# tviic2d6mddr register map
Vendor: Cypress Semiconductor; Series: tviic2d6mddr; File version: 1.0
CPU: CM7 r0p1, little endian, MPU, FPU, VTOR, 3 interrupt priority bits
Registers are 32-bit, read-write, reset 0x0 unless marked. A register's access mark holds for its fields unless they carry their own. Offsets are from the block's base; [hi:lo] are bit positions; lines under a group give offsets from that group; {n}, {i} and the like mark numbered series; 'fields as' and 'values as' point back to an identical list.

## VIDEOSS0 (part 5 of 18) — Video and Graphics Subsystem IP
Base 0x40A00000
0x80000 VIDEOIO group — Video I/O Core
  0x00 SUBIO group — Sub Interface
    0x10000 COMPENG group — Composition Engine
      0x00 COMPENGCFG group — Top-Level
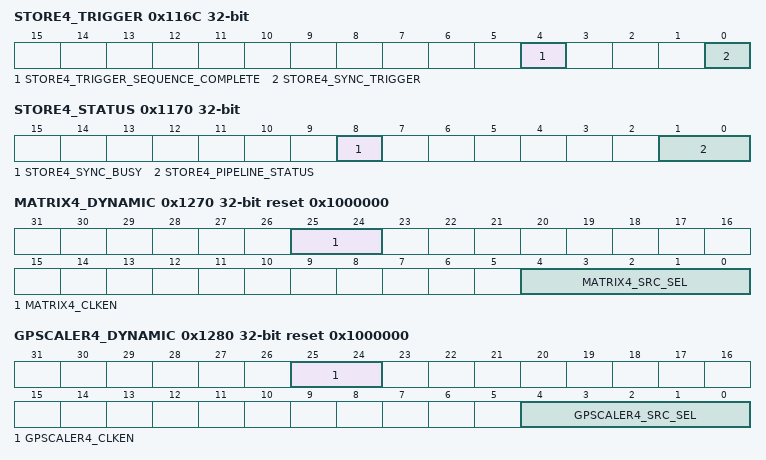
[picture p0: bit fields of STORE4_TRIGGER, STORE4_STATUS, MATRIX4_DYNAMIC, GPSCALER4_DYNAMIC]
        0x116C STORE4_TRIGGER wo reset not defined — Trigger bits for pixel engine configuration of store4
          [4] STORE4_TRIGGER_SEQUENCE_COMPLETE — By writing a '1' to this register field, you can trigger the store4 sequence complete interrupt that will occur as soon as the pipeline with the endpoint store4 is empty. This interrupt will also occur if the pipeline is already empty when this field is written. The interrupt will not occur if this field is not written. The interrupt will occur exactly as often as this field is written, assuming that this field is not written again until the interrupt has occured after a previous trigger.
          [0] STORE4_SYNC_TRIGGER — Writing a '1' to this field triggers reconfiguration of the pipeline with endpoint store4
        0x1170 STORE4_STATUS ro — Status information for pixel engine configuration of store4
          [8] STORE4_SYNC_BUSY — Synchronization busy status of store4 endpoint
            0=IDLE (store4 synchronizer is idle); 1=BUSY (store4 synchronizer is busy)
          [1:0] STORE4_PIPELINE_STATUS — Status of pipeline with endpoint store4
            0=EMPTY (Pipeline with endpoint store4 is empty); 1=RUNNING (Pipeline with endpoint store4 is currently processing one operation); 2=RUNNING_RETRIGGERED (Pipeline with endpoint store4 is currently processing one operation with a second one already kicked to be processed afterwards); 3=RSVD (N/A)
        0x1180 FETCHLAYER0_STATUS ro reset not defined — Status information for pixel engine configuration of fetchlayer0
          [18:16] FETCHLAYER0_SEL — Status of the connection of the fetchlayer0 module
            1=EXTDST0 (fetchlayer0 module is used from extdst0 processing path); 2=EXTDST4 (fetchlayer0 module is used from extdst4 processing path); 3=EXTDST1 (fetchlayer0 module is used from extdst1 processing path); 4=EXTDST5 (fetchlayer0 module is used from extdst5 processing path); 5=STORE4 (fetchlayer0 module is used from store4 processing path); 0=DISABLE (fetchlayer0 module is not used)
        0x11A0 FETCHDECODE4_DYNAMIC — Dynamic pixel engine configuration for fetchdecode4
          [4:0] FETCHDECODE4_SRC_SEL — Selection of the source for the src input of the fetchdecode4 module
            0=DISABLE (Unit fetchdecode4 input port src is disabled); 13=FETCHECO4 (Unit fetchdecode4 input port src is connected to output of unit fetcheco4); 20=GPSCALER4 (Unit fetchdecode4 input port src is connected to output of unit gpscaler4)
        0x11A4 FETCHDECODE4_STATUS ro reset not defined — Status information for pixel engine configuration of fetchdecode4
          [18:16] FETCHDECODE4_SEL — Status of the connection of the fetchdecode4 module
            1=EXTDST0 (fetchdecode4 module is used from extdst0 processing path); 2=EXTDST4 (fetchdecode4 module is used from extdst4 processing path); 3=EXTDST1 (fetchdecode4 module is used from extdst1 processing path); 4=EXTDST5 (fetchdecode4 module is used from extdst5 processing path); 5=STORE4 (fetchdecode4 module is used from store4 processing path); 0=DISABLE (fetchdecode4 module is not used)
        0x11C0 FETCHECO4_STATUS ro reset not defined — Status information for pixel engine configuration of fetcheco4
          [18:16] FETCHECO4_SEL — Status of the connection of the fetcheco4 module
            1=EXTDST0 (fetcheco4 module is used from extdst0 processing path); 2=EXTDST4 (fetcheco4 module is used from extdst4 processing path); 3=EXTDST1 (fetcheco4 module is used from extdst1 processing path); 4=EXTDST5 (fetcheco4 module is used from extdst5 processing path); 5=STORE4 (fetcheco4 module is used from store4 processing path); 0=DISABLE (fetcheco4 module is not used)
        0x1200 FETCHWARP1_DYNAMIC — Dynamic pixel engine configuration for fetchwarp1
          [4:0] FETCHWARP1_SRC_SEL — Selection of the source for the src input of the fetchwarp1 module
            0=DISABLE (Unit fetchwarp1 input port src is disabled); 15=FETCHECO1 (Unit fetchwarp1 input port src is connected to output of unit fetcheco1)
        0x1204 FETCHWARP1_STATUS ro reset not defined — Status information for pixel engine configuration of fetchwarp1
          [18:16] FETCHWARP1_SEL — Status of the connection of the fetchwarp1 module
            1=EXTDST0 (fetchwarp1 module is used from extdst0 processing path); 2=EXTDST4 (fetchwarp1 module is used from extdst4 processing path); 3=EXTDST1 (fetchwarp1 module is used from extdst1 processing path); 4=EXTDST5 (fetchwarp1 module is used from extdst5 processing path); 5=STORE4 (fetchwarp1 module is used from store4 processing path); 0=DISABLE (fetchwarp1 module is not used)
        0x1208 FETCHECO1_STATUS ro reset not defined — Status information for pixel engine configuration of fetcheco1
          [18:16] FETCHECO1_SEL — Status of the connection of the fetcheco1 module
            1=EXTDST0 (fetcheco1 module is used from extdst0 processing path); 2=EXTDST4 (fetcheco1 module is used from extdst4 processing path); 3=EXTDST1 (fetcheco1 module is used from extdst1 processing path); 4=EXTDST5 (fetcheco1 module is used from extdst5 processing path); 5=STORE4 (fetcheco1 module is used from store4 processing path); 0=DISABLE (fetcheco1 module is not used)
        0x1220 FETCHLAYER1_STATUS ro reset not defined — Status information for pixel engine configuration of fetchlayer1
          [18:16] FETCHLAYER1_SEL — Status of the connection of the fetchlayer1 module
            1=EXTDST0 (fetchlayer1 module is used from extdst0 processing path); 2=EXTDST4 (fetchlayer1 module is used from extdst4 processing path); 3=EXTDST1 (fetchlayer1 module is used from extdst1 processing path); 4=EXTDST5 (fetchlayer1 module is used from extdst5 processing path); 5=STORE4 (fetchlayer1 module is used from store4 processing path); 0=DISABLE (fetchlayer1 module is not used)
        0x1240 FETCHDECODE0_DYNAMIC — Dynamic pixel engine configuration for fetchdecode0
          [4:0] FETCHDECODE0_SRC_SEL — Selection of the source for the src input of the fetchdecode0 module
            0=DISABLE (Unit fetchdecode0 input port src is disabled); 15=FETCHECO1 (Unit fetchdecode0 input port src is connected to output of unit fetcheco1); 13=FETCHECO4 (Unit fetchdecode0 input port src is connected to output of unit fetcheco4)
        0x1244 FETCHDECODE0_STATUS ro reset not defined — Status information for pixel engine configuration of fetchdecode0
          [18:16] FETCHDECODE0_SEL — Status of the connection of the fetchdecode0 module
            1=EXTDST0 (fetchdecode0 module is used from extdst0 processing path); 2=EXTDST4 (fetchdecode0 module is used from extdst4 processing path); 3=EXTDST1 (fetchdecode0 module is used from extdst1 processing path); 4=EXTDST5 (fetchdecode0 module is used from extdst5 processing path); 5=STORE4 (fetchdecode0 module is used from store4 processing path); 0=DISABLE (fetchdecode0 module is not used)
        0x1260 GAMMACOR4_DYNAMIC — Dynamic pixel engine configuration for gammacor4
          [4:0] GAMMACOR4_SRC_SEL — Selection of the source for the src input of the gammacor4 module
            0=DISABLE (Unit gammacor4 input port src is disabled); 9=EXTSRC4 (Unit gammacor4 input port src is connected to output of unit extsrc4); 12=FETCHDECODE4 (Unit gammacor4 input port src is connected to output of unit fetchdecode4)
        0x1264 GAMMACOR4_STATUS ro reset not defined — Status information for pixel engine configuration of gammacor4
          [18:16] GAMMACOR4_SEL — Status of the connection of the gammacor4 module
            1=EXTDST0 (gammacor4 module is used from extdst0 processing path); 2=EXTDST4 (gammacor4 module is used from extdst4 processing path); 3=EXTDST1 (gammacor4 module is used from extdst1 processing path); 4=EXTDST5 (gammacor4 module is used from extdst5 processing path); 5=STORE4 (gammacor4 module is used from store4 processing path); 0=DISABLE (gammacor4 module is not used)
        0x1270 MATRIX4_DYNAMIC reset 0x1000000 — Dynamic pixel engine configuration for matrix4
          [25:24] MATRIX4_CLKEN — Enable of matrix4 clock (this setting has to be the same for all modules of one processing pipeline). If a submodule is enabled and FULL is used, then the register [endpoint_name]_clk must be set to 0x80.
            0=DISABLE (Clock for matrix4 is disabled); 1=AUTOMATIC (Clock is enabled if unit is used, frequency is defined by the register setting for this pipeline (see [endpoint_name]_Static register)); 3=FULL (Clock for matrix4 is without gating)
          [4:0] MATRIX4_SRC_SEL — Selection of the source for the src input of the matrix4 module
            0=DISABLE (Unit matrix4 input port src is disabled); 18=GAMMACOR4 (Unit matrix4 input port src is connected to output of unit gammacor4)
        0x1274 MATRIX4_STATUS ro reset not defined — Status information for pixel engine configuration of matrix4
          [18:16] MATRIX4_SEL — Status of the connection of the matrix4 module
            1=EXTDST0 (matrix4 module is used from extdst0 processing path); 2=EXTDST4 (matrix4 module is used from extdst4 processing path); 3=EXTDST1 (matrix4 module is used from extdst1 processing path); 4=EXTDST5 (matrix4 module is used from extdst5 processing path); 5=STORE4 (matrix4 module is used from store4 processing path); 0=DISABLE (matrix4 module is not used)
        0x1280 GPSCALER4_DYNAMIC reset 0x1000000 — Dynamic pixel engine configuration for gpscaler4
          [25:24] GPSCALER4_CLKEN — Enable of gpscaler4 clock (this setting has to be the same for all modules of one processing pipeline). If a submodule is enabled and FULL is used, then the register [endpoint_name]_clk must be set to 0x80.
            0=DISABLE (Clock for gpscaler4 is disabled); 1=AUTOMATIC (Clock is enabled if unit is used, frequency is defined by the register setting for this pipeline (see [endpoint_name]_Static register)); 3=FULL (Clock for gpscaler4 is without gating)
          [4:0] GPSCALER4_SRC_SEL — Selection of the source for the src input of the gpscaler4 module
            0=DISABLE (Unit gpscaler4 input port src is disabled); 19=MATRIX4 (Unit gpscaler4 input port src is connected to output of unit matrix4); 13=FETCHECO4 (Unit gpscaler4 input port src is connected to output of unit fetcheco4)
        0x1284 GPSCALER4_STATUS ro reset not defined — Status information for pixel engine configuration of gpscaler4
          [18:16] GPSCALER4_SEL — Status of the connection of the gpscaler4 module
            1=EXTDST0 (gpscaler4 module is used from extdst0 processing path); 2=EXTDST4 (gpscaler4 module is used from extdst4 processing path); 3=EXTDST1 (gpscaler4 module is used from extdst1 processing path); 4=EXTDST5 (gpscaler4 module is used from extdst5 processing path); 5=STORE4 (gpscaler4 module is used from store4 processing path); 0=DISABLE (gpscaler4 module is not used)
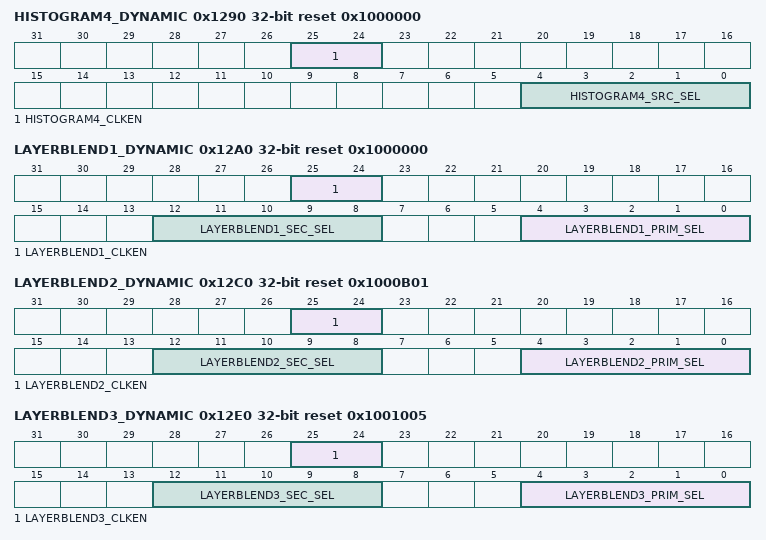
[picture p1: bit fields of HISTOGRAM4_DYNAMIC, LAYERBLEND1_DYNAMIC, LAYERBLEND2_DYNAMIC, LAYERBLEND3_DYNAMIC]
        0x1290 HISTOGRAM4_DYNAMIC reset 0x1000000 — Dynamic pixel engine configuration for histogram4
          [25:24] HISTOGRAM4_CLKEN — Enable of histogram4 clock (this setting has to be the same for all modules of one processing pipeline). If a submodule is enabled and FULL is used, then the register [endpoint_name]_clk must be set to 0x80.
            0=DISABLE (Clock for histogram4 is disabled); 1=AUTOMATIC (Clock is enabled if unit is used, frequency is defined by the register setting for this pipeline (see [endpoint_name]_Static register)); 3=FULL (Clock for histogram4 is without gating)
          [4:0] HISTOGRAM4_SRC_SEL — Selection of the source for the src input of the histogram4 module
            0=DISABLE (Unit histogram4 input port src is disabled); 9=EXTSRC4 (Unit histogram4 input port src is connected to output of unit extsrc4); 12=FETCHDECODE4 (Unit histogram4 input port src is connected to output of unit fetchdecode4); 18=GAMMACOR4 (Unit histogram4 input port src is connected to output of unit gammacor4); 19=MATRIX4 (Unit histogram4 input port src is connected to output of unit matrix4)
        0x1294 HISTOGRAM4_STATUS ro reset not defined — Status information for pixel engine configuration of histogram4
          [18:16] HISTOGRAM4_SEL — Status of the connection of the histogram4 module
            1=EXTDST0 (histogram4 module is used from extdst0 processing path); 2=EXTDST4 (histogram4 module is used from extdst4 processing path); 3=EXTDST1 (histogram4 module is used from extdst1 processing path); 4=EXTDST5 (histogram4 module is used from extdst5 processing path); 5=STORE4 (histogram4 module is used from store4 processing path); 0=DISABLE (histogram4 module is not used)
        0x12A0 LAYERBLEND1_DYNAMIC reset 0x1000000 — Dynamic pixel engine configuration for layerblend1
          [25:24] LAYERBLEND1_CLKEN — Enable of layerblend1 clock (this setting has to be the same for all modules of one processing pipeline). If a submodule is enabled and FULL is used, then the register [endpoint_name]_clk must be set to 0x80.
            0=DISABLE (Clock for layerblend1 is disabled); 1=AUTOMATIC (Clock is enabled if unit is used, frequency is defined by the register setting for this pipeline (see [endpoint_name]_Static register)); 3=FULL (Clock for layerblend1 is without gating)
          [12:8] LAYERBLEND1_SEC_SEL — Selection of the source for the sec input of the layerblend1 module
            0=DISABLE (Unit layerblend1 input port sec is disabled); 12=FETCHDECODE4 (Unit layerblend1 input port sec is connected to output of unit fetchdecode4); 14=FETCHWARP1 (Unit layerblend1 input port sec is connected to output of unit fetchwarp1); 17=FETCHDECODE0 (Unit layerblend1 input port sec is connected to output of unit fetchdecode0); 19=MATRIX4 (Unit layerblend1 input port sec is connected to output of unit matrix4); 20=GPSCALER4 (Unit layerblend1 input port sec is connected to output of unit gpscaler4); 11=FETCHLAYER0 (Unit layerblend1 input port sec is connected to output of unit fetchlayer0); 16=FETCHLAYER1 (Unit layerblend1 input port sec is connected to output of unit fetchlayer1)
          [4:0] LAYERBLEND1_PRIM_SEL — Selection of the source for the prim input of the layerblend1 module
            0=DISABLE (Unit layerblend1 input port prim is disabled); 1=CONSTFRAME0 (Unit layerblend1 input port prim is connected to output of unit constframe0); 5=CONSTFRAME1 (Unit layerblend1 input port prim is connected to output of unit constframe1); 3=CONSTFRAME4 (Unit layerblend1 input port prim is connected to output of unit constframe4); 7=CONSTFRAME5 (Unit layerblend1 input port prim is connected to output of unit constframe5); 19=MATRIX4 (Unit layerblend1 input port prim is connected to output of unit matrix4); 20=GPSCALER4 (Unit layerblend1 input port prim is connected to output of unit gpscaler4); 9=EXTSRC4 (Unit layerblend1 input port prim is connected to output of unit extsrc4)
        {0x1284+0x20*m} LAYERBLEND{m}_STATUS ro reset not defined (m=1..5) — Status information for pixel engine configuration of layerblend{m}
          [18:16] LAYERBLEND{m}_SEL — Status of the connection of the layerblend{m} module
            1=EXTDST0 (layerblend{m} module is used from extdst0 processing path); 2=EXTDST4 (layerblend{m} module is used from extdst4 processing path); 3=EXTDST1 (layerblend{m} module is used from extdst1 processing path); 4=EXTDST5 (layerblend{m} module is used from extdst5 processing path); 5=STORE4 (layerblend{m} module is used from store4 processing path); 0=DISABLE (layerblend{m} module is not used)
        0x12C0 LAYERBLEND2_DYNAMIC reset 0x1000B01 — Dynamic pixel engine configuration for layerblend2
          [25:24] LAYERBLEND2_CLKEN — Enable of layerblend2 clock (this setting has to be the same for all modules of one processing pipeline). If a submodule is enabled and FULL is used, then the register [endpoint_name]_clk must be set to 0x80.
            0=DISABLE (Clock for layerblend2 is disabled); 1=AUTOMATIC (Clock is enabled if unit is used, frequency is defined by the register setting for this pipeline (see [endpoint_name]_Static register)); 3=FULL (Clock for layerblend2 is without gating)
          [12:8] LAYERBLEND2_SEC_SEL — Selection of the source for the sec input of the layerblend2 module
            0=DISABLE (Unit layerblend2 input port sec is disabled); 12=FETCHDECODE4 (Unit layerblend2 input port sec is connected to output of unit fetchdecode4); 14=FETCHWARP1 (Unit layerblend2 input port sec is connected to output of unit fetchwarp1); 17=FETCHDECODE0 (Unit layerblend2 input port sec is connected to output of unit fetchdecode0); 19=MATRIX4 (Unit layerblend2 input port sec is connected to output of unit matrix4); 20=GPSCALER4 (Unit layerblend2 input port sec is connected to output of unit gpscaler4); 11=FETCHLAYER0 (Unit layerblend2 input port sec is connected to output of unit fetchlayer0); 16=FETCHLAYER1 (Unit layerblend2 input port sec is connected to output of unit fetchlayer1)
          [4:0] LAYERBLEND2_PRIM_SEL — Selection of the source for the prim input of the layerblend2 module
            0=DISABLE (Unit layerblend2 input port prim is disabled); 1=CONSTFRAME0 (Unit layerblend2 input port prim is connected to output of unit constframe0); 5=CONSTFRAME1 (Unit layerblend2 input port prim is connected to output of unit constframe1); 3=CONSTFRAME4 (Unit layerblend2 input port prim is connected to output of unit constframe4); 7=CONSTFRAME5 (Unit layerblend2 input port prim is connected to output of unit constframe5); 19=MATRIX4 (Unit layerblend2 input port prim is connected to output of unit matrix4); 20=GPSCALER4 (Unit layerblend2 input port prim is connected to output of unit gpscaler4); 9=EXTSRC4 (Unit layerblend2 input port prim is connected to output of unit extsrc4); 22=LAYERBLEND1 (Unit layerblend2 input port prim is connected to output of unit layerblend1)
        0x12E0 LAYERBLEND3_DYNAMIC reset 0x1001005 — Dynamic pixel engine configuration for layerblend3
          [25:24] LAYERBLEND3_CLKEN — Enable of layerblend3 clock (this setting has to be the same for all modules of one processing pipeline). If a submodule is enabled and FULL is used, then the register [endpoint_name]_clk must be set to 0x80.
            0=DISABLE (Clock for layerblend3 is disabled); 1=AUTOMATIC (Clock is enabled if unit is used, frequency is defined by the register setting for this pipeline (see [endpoint_name]_Static register)); 3=FULL (Clock for layerblend3 is without gating)
          [12:8] LAYERBLEND3_SEC_SEL — Selection of the source for the sec input of the layerblend3 module
            0=DISABLE (Unit layerblend3 input port sec is disabled); 12=FETCHDECODE4 (Unit layerblend3 input port sec is connected to output of unit fetchdecode4); 14=FETCHWARP1 (Unit layerblend3 input port sec is connected to output of unit fetchwarp1); 17=FETCHDECODE0 (Unit layerblend3 input port sec is connected to output of unit fetchdecode0); 19=MATRIX4 (Unit layerblend3 input port sec is connected to output of unit matrix4); 20=GPSCALER4 (Unit layerblend3 input port sec is connected to output of unit gpscaler4); 11=FETCHLAYER0 (Unit layerblend3 input port sec is connected to output of unit fetchlayer0); 16=FETCHLAYER1 (Unit layerblend3 input port sec is connected to output of unit fetchlayer1)
          [4:0] LAYERBLEND3_PRIM_SEL — Selection of the source for the prim input of the layerblend3 module
            0=DISABLE (Unit layerblend3 input port prim is disabled); 1=CONSTFRAME0 (Unit layerblend3 input port prim is connected to output of unit constframe0); 5=CONSTFRAME1 (Unit layerblend3 input port prim is connected to output of unit constframe1); 3=CONSTFRAME4 (Unit layerblend3 input port prim is connected to output of unit constframe4); 7=CONSTFRAME5 (Unit layerblend3 input port prim is connected to output of unit constframe5); 19=MATRIX4 (Unit layerblend3 input port prim is connected to output of unit matrix4); 20=GPSCALER4 (Unit layerblend3 input port prim is connected to output of unit gpscaler4); 9=EXTSRC4 (Unit layerblend3 input port prim is connected to output of unit extsrc4); 23=LAYERBLEND2 (Unit layerblend3 input port prim is connected to output of unit layerblend2); 22=LAYERBLEND1 (Unit layerblend3 input port prim is connected to output of unit layerblend1)
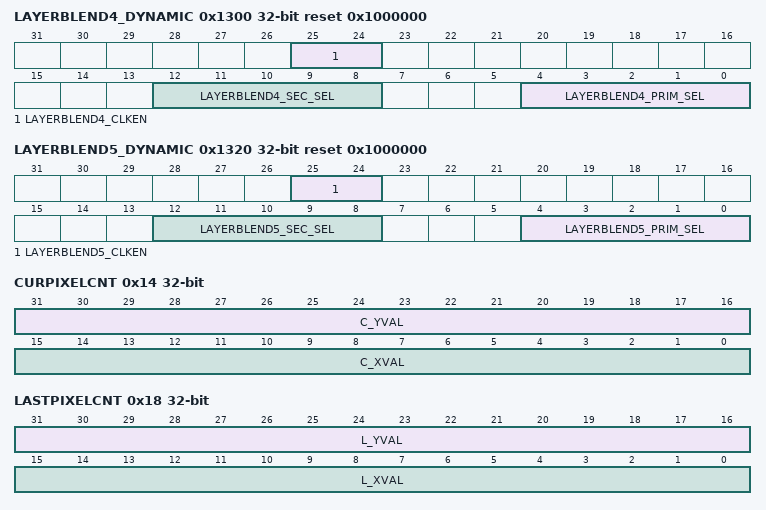
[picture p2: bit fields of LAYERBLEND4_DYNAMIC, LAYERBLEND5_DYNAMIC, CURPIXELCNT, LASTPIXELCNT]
        0x1300 LAYERBLEND4_DYNAMIC reset 0x1000000 — Dynamic pixel engine configuration for layerblend4
          [25:24] LAYERBLEND4_CLKEN — Enable of layerblend4 clock (this setting has to be the same for all modules of one processing pipeline). If a submodule is enabled and FULL is used, then the register [endpoint_name]_clk must be set to 0x80.
            0=DISABLE (Clock for layerblend4 is disabled); 1=AUTOMATIC (Clock is enabled if unit is used, frequency is defined by the register setting for this pipeline (see [endpoint_name]_Static register)); 3=FULL (Clock for layerblend4 is without gating)
          [12:8] LAYERBLEND4_SEC_SEL — Selection of the source for the sec input of the layerblend4 module
            0=DISABLE (Unit layerblend4 input port sec is disabled); 12=FETCHDECODE4 (Unit layerblend4 input port sec is connected to output of unit fetchdecode4); 14=FETCHWARP1 (Unit layerblend4 input port sec is connected to output of unit fetchwarp1); 17=FETCHDECODE0 (Unit layerblend4 input port sec is connected to output of unit fetchdecode0); 19=MATRIX4 (Unit layerblend4 input port sec is connected to output of unit matrix4); 20=GPSCALER4 (Unit layerblend4 input port sec is connected to output of unit gpscaler4); 11=FETCHLAYER0 (Unit layerblend4 input port sec is connected to output of unit fetchlayer0); 16=FETCHLAYER1 (Unit layerblend4 input port sec is connected to output of unit fetchlayer1)
          [4:0] LAYERBLEND4_PRIM_SEL — Selection of the source for the prim input of the layerblend4 module
            0=DISABLE (Unit layerblend4 input port prim is disabled); 1=CONSTFRAME0 (Unit layerblend4 input port prim is connected to output of unit constframe0); 5=CONSTFRAME1 (Unit layerblend4 input port prim is connected to output of unit constframe1); 3=CONSTFRAME4 (Unit layerblend4 input port prim is connected to output of unit constframe4); 7=CONSTFRAME5 (Unit layerblend4 input port prim is connected to output of unit constframe5); 19=MATRIX4 (Unit layerblend4 input port prim is connected to output of unit matrix4); 20=GPSCALER4 (Unit layerblend4 input port prim is connected to output of unit gpscaler4); 9=EXTSRC4 (Unit layerblend4 input port prim is connected to output of unit extsrc4); 24=LAYERBLEND3 (Unit layerblend4 input port prim is connected to output of unit layerblend3); 23=LAYERBLEND2 (Unit layerblend4 input port prim is connected to output of unit layerblend2); 22=LAYERBLEND1 (Unit layerblend4 input port prim is connected to output of unit layerblend1)
        0x1320 LAYERBLEND5_DYNAMIC reset 0x1000000 — Dynamic pixel engine configuration for layerblend5
          [25:24] LAYERBLEND5_CLKEN — Enable of layerblend5 clock (this setting has to be the same for all modules of one processing pipeline). If a submodule is enabled and FULL is used, then the register [endpoint_name]_clk must be set to 0x80.
            0=DISABLE (Clock for layerblend5 is disabled); 1=AUTOMATIC (Clock is enabled if unit is used, frequency is defined by the register setting for this pipeline (see [endpoint_name]_Static register)); 3=FULL (Clock for layerblend5 is without gating)
          [12:8] LAYERBLEND5_SEC_SEL — Selection of the source for the sec input of the layerblend5 module
            0=DISABLE (Unit layerblend5 input port sec is disabled); 12=FETCHDECODE4 (Unit layerblend5 input port sec is connected to output of unit fetchdecode4); 14=FETCHWARP1 (Unit layerblend5 input port sec is connected to output of unit fetchwarp1); 17=FETCHDECODE0 (Unit layerblend5 input port sec is connected to output of unit fetchdecode0); 19=MATRIX4 (Unit layerblend5 input port sec is connected to output of unit matrix4); 20=GPSCALER4 (Unit layerblend5 input port sec is connected to output of unit gpscaler4); 11=FETCHLAYER0 (Unit layerblend5 input port sec is connected to output of unit fetchlayer0); 16=FETCHLAYER1 (Unit layerblend5 input port sec is connected to output of unit fetchlayer1)
          [4:0] LAYERBLEND5_PRIM_SEL — Selection of the source for the prim input of the layerblend5 module
            0=DISABLE (Unit layerblend5 input port prim is disabled); 1=CONSTFRAME0 (Unit layerblend5 input port prim is connected to output of unit constframe0); 5=CONSTFRAME1 (Unit layerblend5 input port prim is connected to output of unit constframe1); 3=CONSTFRAME4 (Unit layerblend5 input port prim is connected to output of unit constframe4); 7=CONSTFRAME5 (Unit layerblend5 input port prim is connected to output of unit constframe5); 19=MATRIX4 (Unit layerblend5 input port prim is connected to output of unit matrix4); 20=GPSCALER4 (Unit layerblend5 input port prim is connected to output of unit gpscaler4); 9=EXTSRC4 (Unit layerblend5 input port prim is connected to output of unit extsrc4); {v}=LAYERBLEND{v-21} (Unit layerblend5 input port prim is connected to output of unit layerblend{v-21}) (v=22..25)
        0x1340 EXTSRC8_STATUS ro reset not defined — Status information for pixel engine configuration of extsrc8
          [18:16] EXTSRC8_SEL — Status of the connection of the extsrc8 module
            1=EXTDST0 (extsrc8 module is used from extdst0 processing path); 2=EXTDST4 (extsrc8 module is used from extdst4 processing path); 3=EXTDST1 (extsrc8 module is used from extdst1 processing path); 4=EXTDST5 (extsrc8 module is used from extdst5 processing path); 5=STORE4 (extsrc8 module is used from store4 processing path); 0=DISABLE (extsrc8 module is not used)
      0x2000 CONSTFRAME0 group — ConstFrame #0 (Content)
        0x00 STATICCONTROL — ConstFrame unit static control register
          [0] SHDEN — Enables shadowing of all RWS type registers (0=write_through, 1=shadowed).
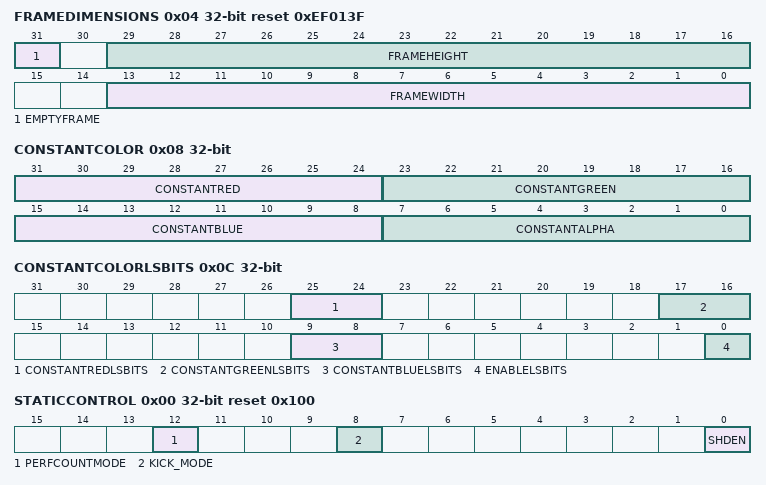
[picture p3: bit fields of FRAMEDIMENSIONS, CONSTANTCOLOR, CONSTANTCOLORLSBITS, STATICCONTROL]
        0x04 FRAMEDIMENSIONS reset 0xEF013F — Output frame dimensions.
          [31] EMPTYFRAME — When enabled output frame is empty. FrameWidth/Height settings have no effect then. Can be used to load shadows or to generate synchronization signals only (frame/sequence complete).
          [29:16] FRAMEHEIGHT — Frame height in pixels minus one.
          [13:0] FRAMEWIDTH — Frame width in pixels minus one.
        0x08 CONSTANTCOLOR — 8-bit constant frame color components.
          [31:24] CONSTANTRED — Red component.
          [23:16] CONSTANTGREEN — Green component.
          [15:8] CONSTANTBLUE — Blue component.
          [7:0] CONSTANTALPHA — Alpha component.
        0x0C CONSTANTCOLORLSBITS — LSBits for 10-bit constant frame color components (optional).
          [25:24] CONSTANTREDLSBITS — LSBits of 10-bit red component.
          [17:16] CONSTANTGREENLSBITS — LSBits of 10-bit green component.
          [9:8] CONSTANTBLUELSBITS — LSBits of 10-bit blue component.
          [0] ENABLELSBITS — If enabled, the two least significant bits of 10-bit color components are taken from this register. Otherwise the two most significant bits from 8-bit values in ConstantColor register are taken.
        0x10 CONTROLTRIGGER wo reset not defined — ConstFrame unit trigger register
          [0] SHDTOKGEN — Writing a 1 to this will load shadow registers into the active configuration with the next start of frame and send a shadow load token to subsequent units.
        0x14 START wo reset not defined — ConstFrame unit start register
          [0] START — Writing a one starts processing, it is recommended to use this for debug purposes only.
      0x2400 EXTDST0 group — ExtDst #0 (Content)
        0x00 STATICCONTROL reset 0x100 — External Destination static control register
          [12] PERFCOUNTMODE — Value 1 enables performance counter mode, which does not generate an output frame but processes input data as fast as possible instead. Can be used to determine the maximum possible read-out performance of display buffers.
          [8] KICK_MODE — Operation mode of generated kick signal
            0=SOFTWARE (kick generation by KICK field only); 1=EXTERNAL (kick signal from external allowed)
          [0] SHDEN — Enables shadowing of all RWS type registers (0=write_through, 1=shadowed).
        0x04 CONTROL — External Destination shadowed control register
          [0] GAMMAAPPLYENABLE — Enable gamma conversion stage to apply gamma function. This gamma function converts the pixel data from linear color space to non-linear color space before they are output.
        0x08 SOFTWAREKICK wo reset not defined — External Destination software kick
          [0] KICK — Software kick, forces a kick signal independent of KICK_MODE. Write 1 to send kick.
        0x0C STATUS — External Destination Unit current status
          [0] CNT_ERR_STS — Pixel count error
        0x10 CONTROLWORD ro reset not defined — Value of last received control word
          [31:0] CW_VAL
        0x14 CURPIXELCNT ro reset not defined — pixel count of currently running frame
          [31:16] C_YVAL — value of vertical line counter, internal counter counting from max-1 to 0
          [15:0] C_XVAL — value of horizontal pixel counter, internal counter counting from max-1 to 0
        0x18 LASTPIXELCNT ro reset not defined — pixel count between last two control words
          [31:16] L_YVAL — value of vertical line counter
          [15:0] L_XVAL — value of horizontal pixel counter
        0x1C PERFCOUNTER ro — Performance counter result
          [31:0] PERFRESULT — Returns the performance counter value. Returns number of cycles of the last frame on the input. To calculate the performance divide the known number of pixels of the frame by this number. For debug purposes only, read when stable only, otherwise read data might be corrupted.
      0x2800 CONSTFRAME4 group — ConstFrame #4 (Safety)
        0x00 STATICCONTROL — ConstFrame unit static control register
          fields as VIDEOIO.SUBIO.COMPENG.CONSTFRAME0.STATICCONTROL
        0x04 FRAMEDIMENSIONS reset 0xEF013F — Output frame dimensions.
          fields as VIDEOIO.SUBIO.COMPENG.CONSTFRAME0.FRAMEDIMENSIONS
        0x08 CONSTANTCOLOR — 8-bit constant frame color components.
          fields as VIDEOIO.SUBIO.COMPENG.CONSTFRAME0.CONSTANTCOLOR
        0x0C CONSTANTCOLORLSBITS — LSBits for 10-bit constant frame color components (optional).
          fields as VIDEOIO.SUBIO.COMPENG.CONSTFRAME0.CONSTANTCOLORLSBITS
        0x10 CONTROLTRIGGER wo reset not defined — ConstFrame unit trigger register
          fields as VIDEOIO.SUBIO.COMPENG.CONSTFRAME0.CONTROLTRIGGER
        0x14 START wo reset not defined — ConstFrame unit start register
          fields as VIDEOIO.SUBIO.COMPENG.CONSTFRAME0.START
      0x2C00 EXTDST4 group — ExtDst #4 (Safety)
        0x00 STATICCONTROL reset 0x100 — External Destination static control register
          fields as VIDEOIO.SUBIO.COMPENG.EXTDST0.STATICCONTROL
        0x04 CONTROL — External Destination shadowed control register
          fields as VIDEOIO.SUBIO.COMPENG.EXTDST0.CONTROL
        0x08 SOFTWAREKICK wo reset not defined — External Destination software kick
          fields as VIDEOIO.SUBIO.COMPENG.EXTDST0.SOFTWAREKICK
